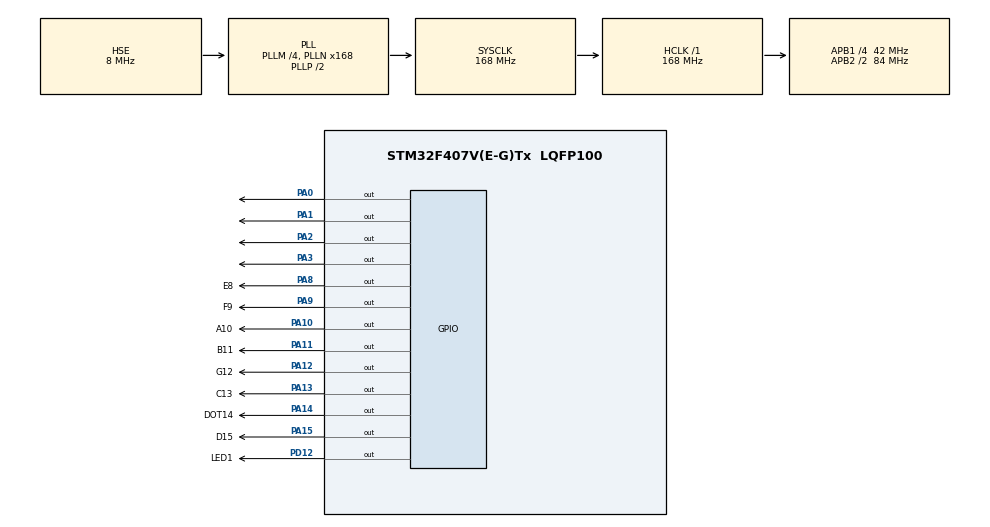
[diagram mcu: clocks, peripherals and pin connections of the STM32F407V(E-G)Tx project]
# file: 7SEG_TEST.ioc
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Mcu.Family=STM32F4
RCC.PLLSourceVirtual=RCC_PLLSOURCE_HSE
PD12.GPIO_Label=LED1
PH0-OSC_IN.Signal=RCC_OSC_IN
RCC.CortexFreq_Value=168000000
PA9.GPIO_Label=F9
PA14.GPIO_Label=DOT14
PA11.GPIO_Label=B11
RCC.APB1CLKDivider=RCC_HCLK_DIV4
PA12.GPIO_Label=G12
RCC.SYSCLKSource=RCC_SYSCLKSOURCE_PLLCLK
ProjectManager.StackSize=0x400
PA0-WKUP.Signal=GPIO_Output
VP_TIM7_VS_ClockSourceINT.Mode=Enable_Timer
PA13.Signal=GPIO_Output
PA15.GPIO_Label=D15
PA12.Signal=GPIO_Output
PA8.GPIO_Label=E8
ProjectManager.TargetToolchain=STM32CubeIDE
RCC.HCLKFreq_Value=168000000
RCC.APB2TimFreq_Value=168000000
PA9.Signal=GPIO_Output
TIM7.Period=8399
RCC.LSE_VALUE=32768
PA1.Signal=GPIO_Output
RCC.AHBFreq_Value=168000000
PH0-OSC_IN.Mode=HSE-External-Oscillator
RCC.HSE_VALUE=8000000
TIM7.Prescaler=9999
board=custom
RCC.VCOOutputFreq_Value=336000000
RCC.APB2Freq_Value=84000000
PA10.GPIO_Label=A10
PH1-OSC_OUT.Signal=RCC_OSC_OUT
PA8.Signal=GPIO_Output
Mcu.Name=STM32F407V(E-G)Tx
PA2.Signal=GPIO_Output
PA13.GPIO_Label=C13
PH1-OSC_OUT.Mode=HSE-External-Oscillator
RCC.48MHZClocksFreq_Value=84000000
RCC.SYSCLKFreq_VALUE=168000000
Mcu.Package=LQFP100
PD12.Signal=GPIO_Output
PA11.Signal=GPIO_Output
PA10.Signal=GPIO_Output
PA14.Signal=GPIO_Output
PA15.Signal=GPIO_Output
ProjectManager.HeapSize=0x200
RCC.HSI_VALUE=16000000
NVIC.PriorityGroup=NVIC_PRIORITYGROUP_4
RCC.APB2CLKDivider=RCC_HCLK_DIV2
RCC.PLLM=4
RCC.PLLN=168
RCC.APB1TimFreq_Value=84000000
RCC.APB1Freq_Value=42000000
NVIC.TIM7_IRQn=true\:0\:0\:false\:false\:true\:true\:true
PA3.Signal=GPIO_Output

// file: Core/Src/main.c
/* USER CODE BEGIN Header */
/**
  ******************************************************************************
  * @file           : main.c
  * @brief          : Main program body
  ******************************************************************************
  * @attention
  *
  * <h2><center>&copy; Copyright (c) 2021 STMicroelectronics.
  * All rights reserved.</center></h2>
  *
  * This software component is licensed by ST under BSD 3-Clause license,
  * the "License"; You may not use this file except in compliance with the
  * License. You may obtain a copy of the License at:
  *                        opensource.org/licenses/BSD-3-Clause
  *
  ******************************************************************************
  */
/* USER CODE END Header */
#include "main.h"
#include "tim.h"
#include "gpio.h"

/* USER CODE BEGIN Includes */
#include <stdio.h>
#include "7seg.h"
/* USER CODE END Includes */

/* USER CODE BEGIN PV */
   static uint8_t nIdx;
/* USER CODE END PV */

void SystemClock_Config(void);

int main(void)
{

  /* MCU Configuration--------------------------------------------------------*/

  /* Reset of all peripherals, Initializes the Flash interface and the Systick. */
  HAL_Init();

  /* Configure the system clock */
  SystemClock_Config();

  /* Initialize all configured peripherals */
  MX_GPIO_Init();
  MX_TIM7_Init();
  /* USER CODE BEGIN 2 */

  HAL_TIM_Base_Start_IT(&htim7);
  /* USER CODE END 2 */

  /* Infinite loop */
  while (1)
  {

  }
}

void SystemClock_Config(void)
{
  RCC_OscInitTypeDef RCC_OscInitStruct = {0};
  RCC_ClkInitTypeDef RCC_ClkInitStruct = {0};

  /** Configure the main internal regulator output voltage
  */
  __HAL_RCC_PWR_CLK_ENABLE();
  __HAL_PWR_VOLTAGESCALING_CONFIG(PWR_REGULATOR_VOLTAGE_SCALE1);
  /** Initializes the RCC Oscillators according to the specified parameters
  * in the RCC_OscInitTypeDef structure.
  */
  RCC_OscInitStruct.OscillatorType = RCC_OSCILLATORTYPE_HSE;
  RCC_OscInitStruct.HSEState = RCC_HSE_ON;
  RCC_OscInitStruct.PLL.PLLState = RCC_PLL_ON;
  RCC_OscInitStruct.PLL.PLLSource = RCC_PLLSOURCE_HSE;
  RCC_OscInitStruct.PLL.PLLM = 4;
  RCC_OscInitStruct.PLL.PLLN = 168;
  RCC_OscInitStruct.PLL.PLLP = RCC_PLLP_DIV2;
  RCC_OscInitStruct.PLL.PLLQ = 4;
  if (HAL_RCC_OscConfig(&RCC_OscInitStruct) != HAL_OK)
  {
    Error_Handler();
  }
  /** Initializes the CPU, AHB and APB buses clocks
  */
  RCC_ClkInitStruct.ClockType = RCC_CLOCKTYPE_HCLK|RCC_CLOCKTYPE_SYSCLK
                              |RCC_CLOCKTYPE_PCLK1|RCC_CLOCKTYPE_PCLK2;
  RCC_ClkInitStruct.SYSCLKSource = RCC_SYSCLKSOURCE_PLLCLK;
  RCC_ClkInitStruct.AHBCLKDivider = RCC_SYSCLK_DIV1;
  RCC_ClkInitStruct.APB1CLKDivider = RCC_HCLK_DIV4;
  RCC_ClkInitStruct.APB2CLKDivider = RCC_HCLK_DIV2;

  if (HAL_RCC_ClockConfig(&RCC_ClkInitStruct, FLASH_LATENCY_5) != HAL_OK)
  {
    Error_Handler();
  }
}

/* USER CODE BEGIN 4 */

void HAL_TIM_PeriodElapsedCallback(TIM_HandleTypeDef *htim)
{

	if (htim->Instance == TIM7)
	{
		HAL_GPIO_TogglePin(LED1_GPIO_Port, LED1_Pin);

		if (HAL_GPIO_ReadPin(LED1_GPIO_Port, LED1_Pin) == GPIO_PIN_SET)
		{
			if (nIdx > 10) nIdx = 0;
			PutFND(nIdx);
			nIdx++;
		}
	}
}

/* USER CODE END 4 */

void Error_Handler(void)
{
  __disable_irq();
  while (1)
  {
  }
}

/************************ (C) COPYRIGHT STMicroelectronics *****END OF FILE****/
